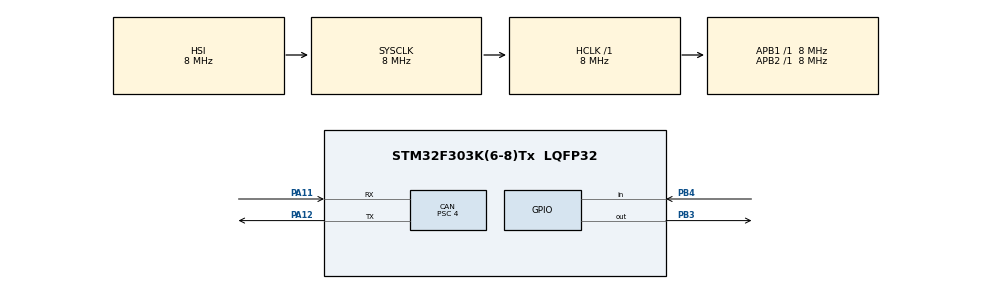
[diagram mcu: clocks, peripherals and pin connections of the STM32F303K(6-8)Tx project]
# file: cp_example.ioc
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CAN.BS1=CAN_BS1_2TQ
CAN.BS2=CAN_BS2_1TQ
CAN.CalculateTimeBit=2000
CAN.CalculateTimeQuantum=500.0
CAN.Prescaler=4
CAN.TXFP=ENABLE
Mcu.Family=STM32F3
Mcu.Name=STM32F303K(6-8)Tx
Mcu.Package=LQFP32
NVIC.CAN_RX0_IRQn=true\:0\:0\:false\:false\:true
NVIC.CAN_RX1_IRQn=true\:0\:0\:false\:false\:true
NVIC.CAN_SCE_IRQn=true\:0\:0\:false\:false\:true
NVIC.CAN_TX_IRQn=true\:0\:0\:false\:false\:true
NVIC.PriorityGroup=NVIC_PRIORITYGROUP_4
PA11.Mode=Master
PA11.Signal=CAN_RX
PA12.Mode=Master
PA12.Signal=CAN_TX
PB3.Signal=GPIO_Output
PB4.GPIO_PuPd=GPIO_PULLDOWN
PB4.Signal=GPIO_Input
ProjectManager.HeapSize=0x200
ProjectManager.StackSize=0x400
ProjectManager.TargetToolchain=SW4STM32
RCC.ADC1Enable=false
RCC.ADC2Enable=false
RCC.ADC3Enable=false
RCC.ADC4Enable=false
RCC.AHBFreq_Value=8000000
RCC.APB1Freq_Value=8000000
RCC.APB2Freq_Value=8000000
RCC.ClockTypeHCLK=RCC_CLOCKTYPE_HCLK
RCC.ClockTypePCLK1=RCC_CLOCKTYPE_PCLK1
RCC.ClockTypePCLK2=RCC_CLOCKTYPE_PCLK2
RCC.CortexFreq_Value=8000000
RCC.EnableHSE=false
RCC.EnableHSERTCDevisor=false
RCC.EnableHSIRTCDevisor=false
RCC.EnableLSE=false
RCC.EnableLSERTC=false
RCC.EnableMCOMultDivisor=false
RCC.FLITFCLKFEnable=false
RCC.HRTIMEnable=false
RCC.HSEState=RCC_HSE_OFF
RCC.HSE_VALUE=8000000
RCC.HSIState=RCC_HSI_ON
RCC.HSI_VALUE=8000000
RCC.I2C1Enable=false
RCC.I2C2Enable=false
RCC.I2C3Enable=false
RCC.I2SEnable=false
RCC.IWDGEnable=false
RCC.LSIState=RCC_LSI_OFF
RCC.MCOEnable=false
RCC.OscillatorTypeHSI=RCC_OSCILLATORTYPE_HSI
RCC.PLLSource=RCC_PLLSOURCE_HSI
RCC.PLLSourceVirtual=RCC_PLLSOURCE_HSI
RCC.PLLState=RCC_PLL_OFF
RCC.RTCEnable=false
RCC.SYSCLKFreq_VALUE=8000000
RCC.SYSCLKSource=RCC_SYSCLKSOURCE_HSI
RCC.SYSCLKSourceVirtual=RCC_SYSCLKSOURCE_HSI
RCC.Tim15Enable=false
RCC.Tim16Enable=false
RCC.Tim17Enable=false
RCC.Tim1Enable=false
RCC.Tim8Enable=true
RCC.UART4Enable=false
RCC.UART5Enable=false
RCC.USART1Enable=false
RCC.USART2Enable=false
RCC.USART3Enable=false
RCC.USBEnable=false
board=cp_example

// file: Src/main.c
/**
  ******************************************************************************
  * File Name          : main.c
  * Description        : Main program body
  ******************************************************************************
  *
  * COPYRIGHT(c) 2017 STMicroelectronics
  *
  * Redistribution and use in source and binary forms, with or without modification,
  * are permitted provided that the following conditions are met:
  *   1. Redistributions of source code must retain the above copyright notice,
  *      this list of conditions and the following disclaimer.
  *   2. Redistributions in binary form must reproduce the above copyright notice,
  *      this list of conditions and the following disclaimer in the documentation
  *      and/or other materials provided with the distribution.
  *   3. Neither the name of STMicroelectronics nor the names of its contributors
  *      may be used to endorse or promote products derived from this software
  *      without specific prior written permission.
  *
  * THIS SOFTWARE IS PROVIDED BY THE COPYRIGHT HOLDERS AND CONTRIBUTORS "AS IS"
  * AND ANY EXPRESS OR IMPLIED WARRANTIES, INCLUDING, BUT NOT LIMITED TO, THE
  * IMPLIED WARRANTIES OF MERCHANTABILITY AND FITNESS FOR A PARTICULAR PURPOSE ARE
  * DISCLAIMED. IN NO EVENT SHALL THE COPYRIGHT HOLDER OR CONTRIBUTORS BE LIABLE
  * FOR ANY DIRECT, INDIRECT, INCIDENTAL, SPECIAL, EXEMPLARY, OR CONSEQUENTIAL
  * DAMAGES (INCLUDING, BUT NOT LIMITED TO, PROCUREMENT OF SUBSTITUTE GOODS OR
  * SERVICES; LOSS OF USE, DATA, OR PROFITS; OR BUSINESS INTERRUPTION) HOWEVER
  * CAUSED AND ON ANY THEORY OF LIABILITY, WHETHER IN CONTRACT, STRICT LIABILITY,
  * OR TORT (INCLUDING NEGLIGENCE OR OTHERWISE) ARISING IN ANY WAY OUT OF THE USE
  * OF THIS SOFTWARE, EVEN IF ADVISED OF THE POSSIBILITY OF SUCH DAMAGE.
  *
  ******************************************************************************
  */
#include "main.h"
#include "stm32f3xx_hal.h"
#include "can.h"
#include "gpio.h"

/* USER CODE BEGIN Includes */
#include "cp_user.h"
/* USER CODE END Includes */

/* USER CODE BEGIN PV */
/* Private variables ---------------------------------------------------------*/

/* USER CODE END PV */

void SystemClock_Config(void);
void Error_Handler(void);

/* USER CODE BEGIN PFP */
/* Private function prototypes -----------------------------------------------*/

/* USER CODE END PFP */

int main(void)
{

  /* MCU Configuration----------------------------------------------------------*/

  /* Reset of all peripherals, Initializes the Flash interface and the Systick. */
  HAL_Init();

  /* Configure the system clock */
  SystemClock_Config();

  /* Initialize all configured peripherals */
  MX_GPIO_Init();
  MX_CAN_Init();

  /* USER CODE BEGIN 2 */
  CP_CAN_Init();
  /* USER CODE END 2 */

  /* Infinite loop */
  /* USER CODE BEGIN WHILE */
  CP_example();
  while (1)
  {
  /* USER CODE END WHILE */

  }

}

/** System Clock Configuration
*/
void SystemClock_Config(void)
{

  RCC_OscInitTypeDef RCC_OscInitStruct;
  RCC_ClkInitTypeDef RCC_ClkInitStruct;

    /**Initializes the CPU, AHB and APB busses clocks
    */
  RCC_OscInitStruct.OscillatorType = RCC_OSCILLATORTYPE_HSI;
  RCC_OscInitStruct.HSIState = RCC_HSI_ON;
  RCC_OscInitStruct.HSICalibrationValue = 16;
  RCC_OscInitStruct.PLL.PLLState = RCC_PLL_NONE;
  if (HAL_RCC_OscConfig(&RCC_OscInitStruct) != HAL_OK)
  {
    Error_Handler();
  }

    /**Initializes the CPU, AHB and APB busses clocks
    */
  RCC_ClkInitStruct.ClockType = RCC_CLOCKTYPE_HCLK|RCC_CLOCKTYPE_SYSCLK
                              |RCC_CLOCKTYPE_PCLK1|RCC_CLOCKTYPE_PCLK2;
  RCC_ClkInitStruct.SYSCLKSource = RCC_SYSCLKSOURCE_HSI;
  RCC_ClkInitStruct.AHBCLKDivider = RCC_SYSCLK_DIV1;
  RCC_ClkInitStruct.APB1CLKDivider = RCC_HCLK_DIV1;
  RCC_ClkInitStruct.APB2CLKDivider = RCC_HCLK_DIV1;

  if (HAL_RCC_ClockConfig(&RCC_ClkInitStruct, FLASH_LATENCY_0) != HAL_OK)
  {
    Error_Handler();
  }

    /**Configure the Systick interrupt time
    */
  HAL_SYSTICK_Config(HAL_RCC_GetHCLKFreq()/1000);

    /**Configure the Systick
    */
  HAL_SYSTICK_CLKSourceConfig(SYSTICK_CLKSOURCE_HCLK);

  /* SysTick_IRQn interrupt configuration */
  HAL_NVIC_SetPriority(SysTick_IRQn, 0, 0);
}

void Error_Handler(void)
{
  while(1)
  {
  }
}

/************************ (C) COPYRIGHT STMicroelectronics *****END OF FILE****/
